# Spirit3 register map
File version: 1.0
CPU: CM0+ r0p0, little endian, no MPU, no FPU, 2 interrupt priority bits
Registers are 32-bit, read-write, reset 0x0 unless marked. A register's access mark holds for its fields unless they carry their own. Offsets are from the block's base; [hi:lo] are bit positions.

## RCC — Reset and clock control
Base 0x48400000
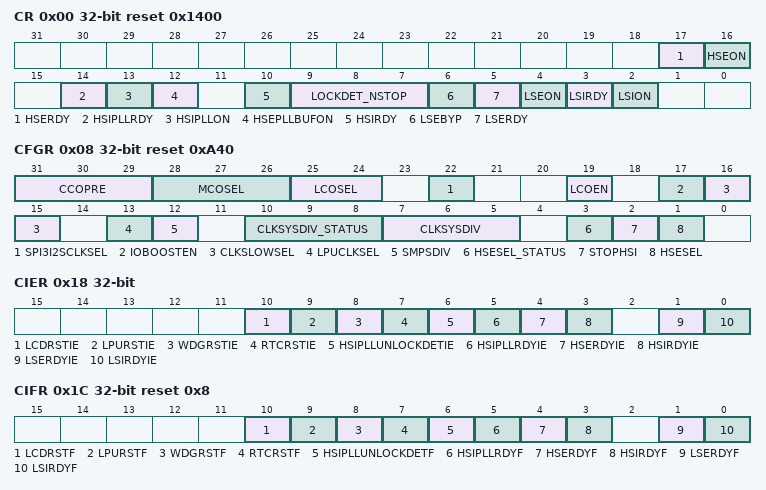
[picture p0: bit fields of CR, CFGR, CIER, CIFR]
0x00 CR reset 0x1400 — Clock control register
  [17] HSERDY ro — External High Speed clock flag
  [16] HSEON — External High Speed clock enable
  [14] HSIPLLRDY — Internal High Speed clock PLL flag. This bit is set by hardware to indicate that the RC64MPLL pll is locked
  [13] HSIPLLON — Internal High Speed clock PLL enable
  [12] HSEPLLBUFON — External high speed clock buffer for PLL RF2G4 enable
  [10] HSIRDY ro — HSI clock ready flag
  [9:7] LOCKDET_NSTOP
  [6] LSEBYP — External Low Speed clock bypass
  [5] LSERDY ro — External Low Speed clock flag
  [4] LSEON — External Low Speed clock enable
  [3] LSIRDY ro — Internal Low Speed clock flag
  [2] LSION — Internal low speed RC clock enable
0x08 CFGR reset 0xA40 — Clock configuration register
  [31:29] CCOPRE — Configurable Clock Output Prescaler
  [28:26] MCOSEL — Microcontroller clock output
  [25:24] LCOSEL — Low speed Configurable Clock Output Selection
  [22] SPI3I2SCLKSEL — Selection of I2s clock for SPI2 IP
  [19] LCOEN — LCO enable on PA10 also in deepstop
  [17] IOBOOSTEN — IO BOOSTER external clock enable
  [16:15] CLKSLOWSEL — low speed clock source selection
  [13] LPUCLKSEL — Selection of LPUART clock
  [12] SMPSDIV — SMPs clock prescaling factor
  [10:8] CLKSYSDIV_STATUS — system clock frequency status
  [7:5] CLKSYSDIV — system clock divided factor from HSI_64M
  [3] HSESEL_STATUS — Clock source selection status
  [2] STOPHSI — RC64MPLL clock source stop request
  [1] HSESEL — Clock source selection request
0x18 CIER — Clock interrupt enable register
  [10] LCDRSTIE — LCD reset release interrupt enable
  [9] LPURSTIE — LPUART reset release interrupt enable
  [8] WDGRSTIE — Watchdog reset release interrupt enable
  [7] RTCRSTIE — RTC reset release interrupt enable
  [6] HSIPLLUNLOCKDETIE — HSI PLL unlock detection interrupt enable
  [5] HSIPLLRDYIE — HSI PLLSYs ready interrupt enable
  [4] HSERDYIE — HSE ready interrupt enable
  [3] HSIRDYIE — HSI ready interrupt enable
  [1] LSERDYIE — LSE ready interrupt enable
  [0] LSIRDYIE — LSI1 ready interrupt enable
0x1C CIFR reset 0x8 — Clock interrupt flag register
  [10] LCDRSTF — LCD reset release flag
  [9] LPURSTF — LPUART reset release flag
  [8] WDGRSTF — Watchdog reset release flag
  [7] RTCRSTF — RTC reset release flag
  [6] HSIPLLUNLOCKDETF — HSI PLL unlock detection flag
  [5] HSIPLLRDYF — HSI PLL ready flag
  [4] HSERDYF — HSE ready interrupt flag
  [3] HSIRDYF — HSI ready interrupt flag
  [1] LSERDYF — LSE ready interrupt flag
  [0] LSIRDYF — LSI1 ready interrupt flag
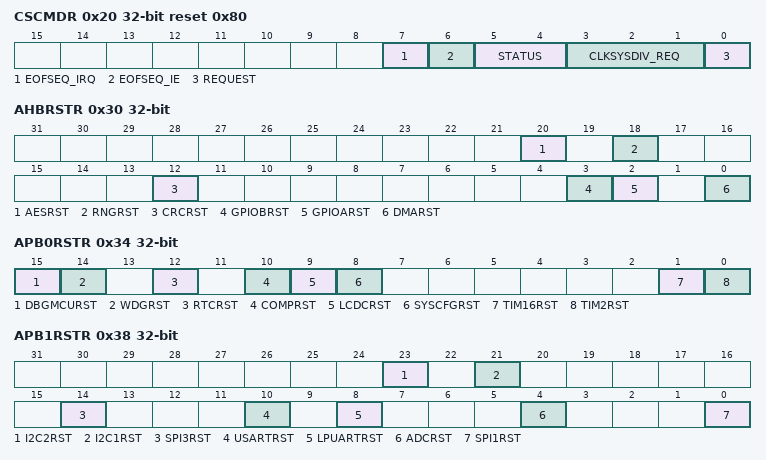
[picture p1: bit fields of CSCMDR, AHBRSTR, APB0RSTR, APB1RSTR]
0x20 CSCMDR reset 0x80 — This register allows switching the CPU system clock frequency safely while the MR_BLE is active
  [7] EOFSEQ_IRQ — End of sequence flag
  [6] EOFSEQ_IE — End of sequence interrupt enable
  [5:4] STATUS — Status of the switching sequence
  [3:1] CLKSYSDIV_REQ — System clock requested/targeted frequency
  [0] REQUEST — Request to switch the system clock frequency
0x30 AHBRSTR — AHB0 macro cells reset register
  [20] AESRST — AES reset
  [18] RNGRST — RNG reset
  [12] CRCRST — CRC reset
  [3] GPIOBRST — IO controller for port A reset
  [2] GPIOARST — IO controller for port B reset
  [0] DMARST — DMA and DMAMUX reset
0x34 APB0RSTR — APB0 macro cells reset register
  [15] DBGMCURST — DBGMCU reset
  [14] WDGRST — Watchdog reset
  [12] RTCRST — RTC reset
  [10] COMPRST — Comparator controller reset
  [9] LCDCRST — LCD controller reset
  [8] SYSCFGRST — system controller reset
  [1] TIM16RST — TIM16 reset
  [0] TIM2RST — TIM2 reset
0x38 APB1RSTR — APB1 peripheral reset register 1
  [23] I2C2RST — I2C2 reset
  [21] I2C1RST — I2C1 reset
  [14] SPI3RST — SPI3 reset
  [10] USARTRST — USARTRST: USART reset
  [8] LPUARTRST — LPUART reset
  [4] ADCRST — ADC reset
  [0] SPI1RST — SPI1 reset
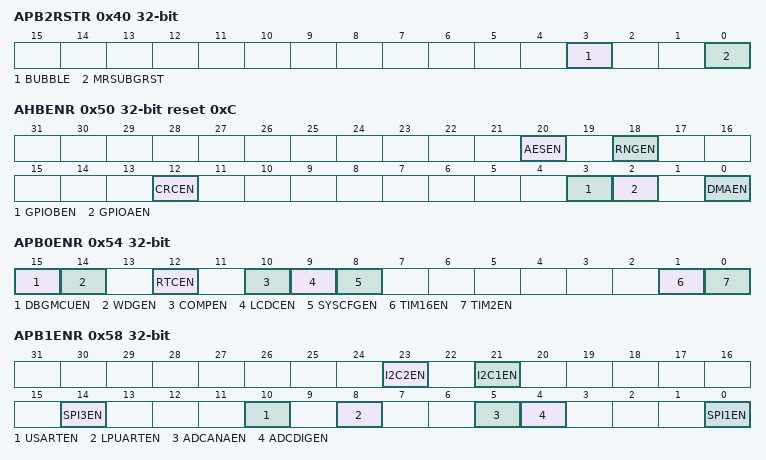
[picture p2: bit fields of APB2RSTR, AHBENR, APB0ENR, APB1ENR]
0x40 APB2RSTR — APB2 peripheral reset register 2
  [3] BUBBLE — Bubble RFIP reset
  [0] MRSUBGRST — MR_SUBG (SubG radio) reset
0x50 AHBENR reset 0xC — AHB0 macro cells clock enable register
  [20] AESEN — AES clock enable
  [18] RNGEN — RNG clock enable
  [12] CRCEN — CRCEN: CRC enable
  [3] GPIOBEN — IO controller for port B enable
  [2] GPIOAEN — IO controller for port A enable
  [0] DMAEN — DMA and DMAMUX enable
0x54 APB0ENR — APB0 macro cells clock enable register
  [15] DBGMCUEN — DBGMCU enable
  [14] WDGEN — Watchdog enable
  [12] RTCEN — RTC enable
  [10] COMPEN — Comparator controller enable
  [9] LCDCEN — LCD enable
  [8] SYSCFGEN — system controller enable
  [1] TIM16EN — TIM16 enable
  [0] TIM2EN — TIM2 enable
0x58 APB1ENR
  [23] I2C2EN — I2C2 enable
  [21] I2C1EN — CPU1 I2C1 clock enable
  [14] SPI3EN — CPU1 SPI3 clock enable
  [10] USARTEN — USART enable
  [8] LPUARTEN — LPUART enable
  [5] ADCANAEN — ADCANA enable
  [4] ADCDIGEN — ADCDIG enable
  [0] SPI1EN — SPI1 enable
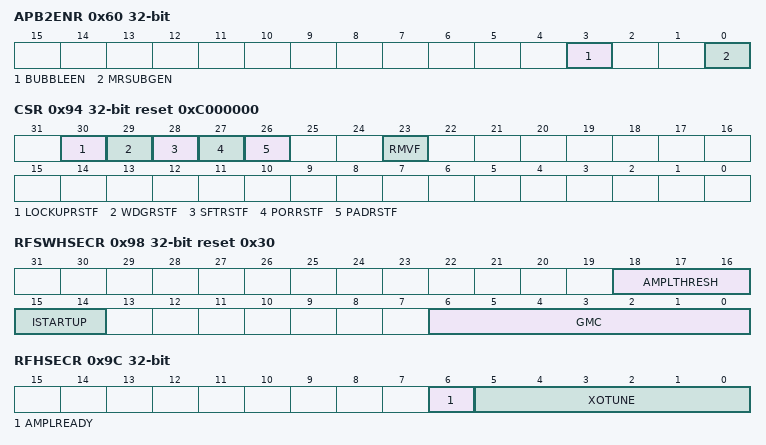
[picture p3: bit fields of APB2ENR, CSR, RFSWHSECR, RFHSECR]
0x60 APB2ENR
  [3] BUBBLEEN — Bubble enable
  [0] MRSUBGEN — MR_SUBG enable
0x94 CSR reset 0xC000000
  [30] LOCKUPRSTF ro — CPU lockup reset flag
  [29] WDGRSTF ro — Watchdog reset flag
  [28] SFTRSTF ro — Software reset flag
  [27] PORRSTF ro — Power-On reset flag
  [26] PADRSTF ro — NRSTn pad reset flag
  [23] RMVF — Remove Flag reset
0x98 RFSWHSECR reset 0x30 — RF Software High Speed External register
  [18:16] AMPLTHRESH — RF-HSE Amplitude Control threshold
  [15:14] ISTARTUP — RF-HSE Startup current
  [6:0] GMC — High speed external XO current control
0x9C RFHSECR ro — RF High Speed External register
  [6] AMPLREADY — RF-HSE Amplitude Control Ready output
  [5:0] XOTUNE — RF-HSE capacitor bank tuning
